# f28p65x_epwm_regs register map
Vendor: Texas Instruments
Peripheral module from a debugger description file (folder C2000).
Address unit: 16 bits
Registers are 16-bit, read-write, no defined reset value unless marked. A register's access mark holds for its fields unless they carry their own. Offsets are as the file gives them; lines under a group give offsets from that group; [hi:lo] are bit positions; {n}, {i} and the like mark numbered series; 'fields as' and 'values as' point back to an identical list; <NAME> marks a mode.

## EPWM_REGS — EPWM Registers
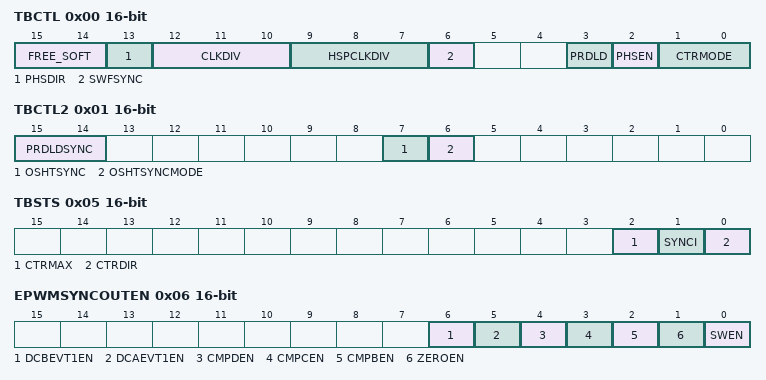
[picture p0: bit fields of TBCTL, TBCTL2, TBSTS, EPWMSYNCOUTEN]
0x00 TBCTL — Time Base Control Register
  [15:14] FREE_SOFT — Emulation Mode Bits
  [13] PHSDIR — Phase Direction Bit
  [12:10] CLKDIV — Time Base Clock Pre-scaler
  [9:7] HSPCLKDIV — High Speed TBCLK Pre-scaler
  [6] SWFSYNC — Software Force Sync Pulse
  [3] PRDLD — Active Period Load
  [2] PHSEN — Phase Load Enable
  [1:0] CTRMODE — Counter Mode
0x01 TBCTL2 — Time Base Control Register 2
  [15:14] PRDLDSYNC — PRD Shadow to Active Load on SYNC Event
  [7] OSHTSYNC — One shot sync
  [6] OSHTSYNCMODE — One shot sync mode
0x03 EPWMSYNCINSEL — EPWMxSYNCIN Source Select Register
  [6:0] SEL — EPWMxSYNCI source select
0x04 TBCTR — Time Base Counter Register
  [15:0] TBCTR — Counter Value
0x05 TBSTS access per field — Time Base Status Register
  [2] CTRMAX rw — Counter Max Latched Status
  [1] SYNCI rw — External Input Sync Status
  [0] CTRDIR ro — Counter Direction Status
0x06 EPWMSYNCOUTEN — EPWMxSYNCOUT Source Enable Register
  [6] DCBEVT1EN — EPWMxSYNCO Digital Compare B Event 1 Sync Enable
  [5] DCAEVT1EN — EPWMxSYNCO Digital Compare A Event 1 Sync Enable
  [4] CMPDEN — EPWMxSYNCO Compare D Event Enable
  [3] CMPCEN — EPWMxSYNCO Compare C Event Enable
  [2] CMPBEN — EPWMxSYNCO Compare B Event Enable
  [1] ZEROEN — EPWMxSYNCO Zero Count Event Enable
  [0] SWEN — EPWMxSYNCO Software Force Enable
0x07 TBCTL3 — Time Base Control Register 3
  [0] OSSFRCEN — One Shot Sync Force Enable
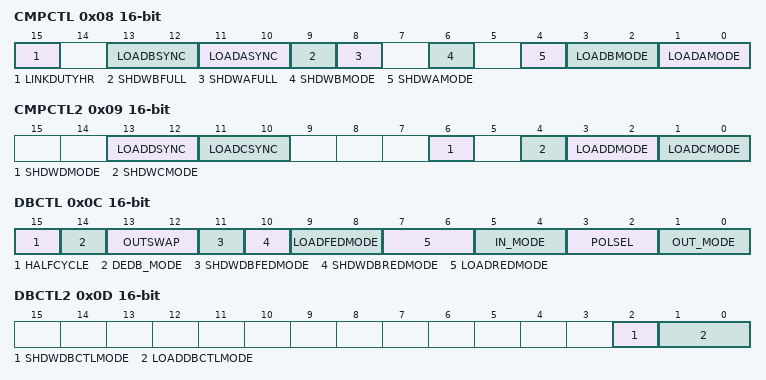
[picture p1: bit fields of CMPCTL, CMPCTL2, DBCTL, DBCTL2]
0x08 CMPCTL access per field — Counter Compare Control Register
  [15] LINKDUTYHR rw — Enable same values on CMPAHR/CMPBHR
  [13:12] LOADBSYNC rw — Active Compare B Load on SYNC
  [11:10] LOADASYNC rw — Active Compare A Load on SYNC
  [9] SHDWBFULL ro — Compare B Shadow Register Full Status
  [8] SHDWAFULL ro — Compare A Shadow Register Full Status
  [6] SHDWBMODE rw — Compare B Register Block Operating Mode
  [4] SHDWAMODE rw — Compare A Register Block Operating Mode
  [3:2] LOADBMODE rw — Active Compare B Load
  [1:0] LOADAMODE rw — Active Compare A Load
0x09 CMPCTL2 — Counter Compare Control Register 2
  [13:12] LOADDSYNC — Active Compare D Load on SYNC
  [11:10] LOADCSYNC — Active Compare C Load on SYNC
  [6] SHDWDMODE — Compare D Block Operating Mode
  [4] SHDWCMODE — Compare C Block Operating Mode
  [3:2] LOADDMODE — Active Compare D load
  [1:0] LOADCMODE — Active Compare C Load
0x0C DBCTL — Dead-Band Generator Control Register
  [15] HALFCYCLE — Half Cycle Clocking Enable
  [14] DEDB_MODE — Dead Band Dual-Edge B Mode Control
  [13:12] OUTSWAP — Dead Band Output Swap Control
  [11] SHDWDBFEDMODE — DBFED Block Operating Mode
  [10] SHDWDBREDMODE — DBRED Block Operating Mode
  [9:8] LOADFEDMODE — Active DBFED Load Mode
  [7:6] LOADREDMODE — Active DBRED Load Mode
  [5:4] IN_MODE — Dead Band Input Select Mode Control
  [3:2] POLSEL — Polarity Select Control
  [1:0] OUT_MODE — Dead Band Output Mode Control
0x0D DBCTL2 — Dead-Band Generator Control Register 2
  [2] SHDWDBCTLMODE — DBCTL Load mode Select
  [1:0] LOADDBCTLMODE — DBCTL Load from Shadow Mode Select
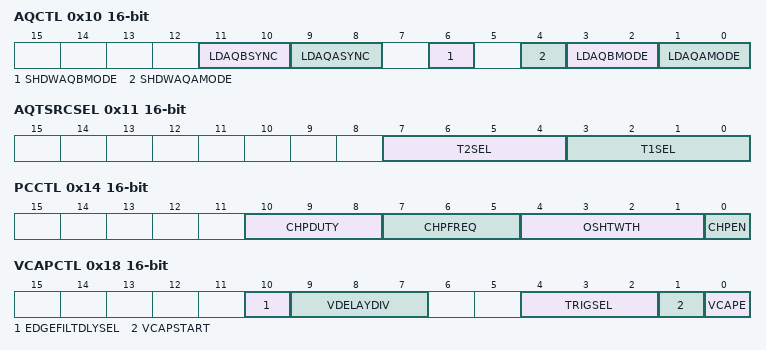
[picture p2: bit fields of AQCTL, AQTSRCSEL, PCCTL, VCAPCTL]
0x10 AQCTL — Action Qualifier Control Register
  [11:10] LDAQBSYNC — AQCTLB Register Load on SYNC
  [9:8] LDAQASYNC — AQCTLA Register Load on SYNC
  [6] SHDWAQBMODE — Action Qualifier B Operating Mode
  [4] SHDWAQAMODE — Action Qualifer A Operating Mode
  [3:2] LDAQBMODE — Action Qualifier B Load Select
  [1:0] LDAQAMODE — Action Qualifier A Load Select
0x11 AQTSRCSEL — Action Qualifier Trigger Event Source Select Register
  [7:4] T2SEL — T2 Event Source Select Bits
  [3:0] T1SEL — T1 Event Source Select Bits
0x14 PCCTL — PWM Chopper Control Register
  [10:8] CHPDUTY — Chopping clock Duty cycle
  [7:5] CHPFREQ — Chopping clock frequency
  [4:1] OSHTWTH — One-shot pulse width
  [0] CHPEN — PWM chopping enable
0x18 VCAPCTL — Valley Capture Control Register
  [10] EDGEFILTDLYSEL — Valley Switching Mode Delay Select
  [9:7] VDELAYDIV — Valley Delay Mode Divide Enable
  [4:2] TRIGSEL — Capture Trigger Select
  [1] VCAPSTART — Valley Capture Start
  [0] VCAPE — Valley Capture mode
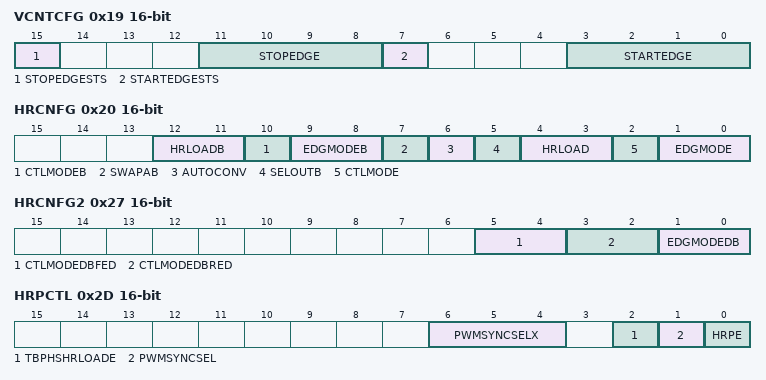
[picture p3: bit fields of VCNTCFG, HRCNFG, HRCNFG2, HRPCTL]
0x19 VCNTCFG access per field — Valley Counter Config Register
  [15] STOPEDGESTS ro — Stop Edge Status Bit
  [11:8] STOPEDGE rw — Counter Start Edge Selection
  [7] STARTEDGESTS ro — Start Edge Status Bit
  [3:0] STARTEDGE rw — Counter Start Edge Selection
0x20 HRCNFG — HRPWM Configuration Register
  [12:11] HRLOADB — ePWMxB Shadow Mode Select Bits
  [10] CTLMODEB — ePWMxB Control Mode Select Bits
  [9:8] EDGMODEB — ePWMxB Edge Mode Select Bits
  [7] SWAPAB — Swap EPWMA and EPWMB Outputs Bit
  [6] AUTOCONV — Autoconversion Bit
  [5] SELOUTB — EPWMB Output Selection Bit
  [4:3] HRLOAD — ePWMxA Shadow Mode Select Bits
  [2] CTLMODE — ePWMxA Control Mode Select Bits
  [1:0] EDGMODE — ePWMxA Edge Mode Select Bits
0x27 HRCNFG2 — HRPWM Configuration 2 Register
  [5:4] CTLMODEDBFED — DBFED Control Mode Select Bits
  [3:2] CTLMODEDBRED — DBRED Control Mode Select Bits
  [1:0] EDGMODEDB — Dead-Band Edge-Mode Select Bits
0x2D HRPCTL — High Resolution Period Control Register
  [6:4] PWMSYNCSELX — EPWMSYNCPER Extended Source Select Bit:
  [2] TBPHSHRLOADE — TBPHSHR Load Enable
  [1] PWMSYNCSEL — EPWMSYNCPER Source Select
  [0] HRPE — High Resolution Period Enable
0x2E TRREM — HRPWM High Resolution Remainder Register
  [10:0] TRREM — HRPWM Remainder Bits
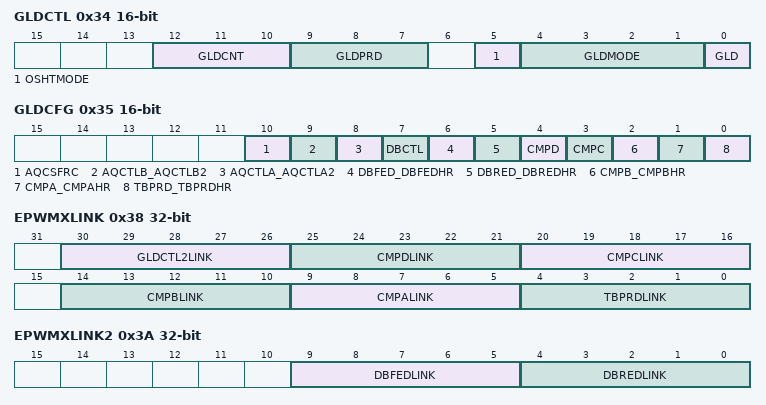
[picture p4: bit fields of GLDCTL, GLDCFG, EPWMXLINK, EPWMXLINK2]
0x34 GLDCTL access per field — Global PWM Load Control Register
  [12:10] GLDCNT ro — Global Load Strobe Counter Register
  [9:7] GLDPRD rw — Global Load Strobe Period Select Register
  [5] OSHTMODE rw — One Shot Load mode control bit
  [4:1] GLDMODE rw — Shadow to Active Global Load Pulse Selection
  [0] GLD rw — Global Shadow to Active load event control
0x35 GLDCFG — Global PWM Load Config Register
  [10] AQCSFRC — Global load event configuration for AQCSFRC
  [9] AQCTLB_AQCTLB2 — Global load event configuration for AQCTLB/B2
  [8] AQCTLA_AQCTLA2 — Global load event configuration for AQCTLA/A2
  [7] DBCTL — Global load event configuration for DBCTL
  [6] DBFED_DBFEDHR — Global load event configuration for DBFED:DBFEDHR
  [5] DBRED_DBREDHR — Global load event configuration for DBRED:DBREDHR
  [4] CMPD — Global load event configuration for CMPD
  [3] CMPC — Global load event configuration for CMPC
  [2] CMPB_CMPBHR — Global load event configuration for CMPB:CMPBHR
  [1] CMPA_CMPAHR — Global load event configuration for CMPA:CMPAHR
  [0] TBPRD_TBPRDHR — Global load event configuration for TBPRD:TBPRDHR
0x38 EPWMXLINK 32-bit
  [30:26] GLDCTL2LINK
  [25:21] CMPDLINK
  [20:16] CMPCLINK
  [14:10] CMPBLINK — CMPB:CMPBHR Link
  [9:5] CMPALINK — CMPA:CMPAHR Link
  [4:0] TBPRDLINK — TBPRD:TBPRDHR Link
0x3A EPWMXLINK2 32-bit
  [9:5] DBFEDLINK — DBFED:DBFEDHR Link
  [4:0] DBREDLINK — DBRED:DBREDHR Link
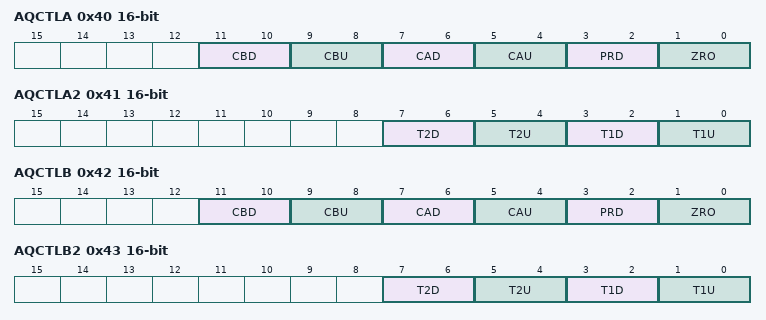
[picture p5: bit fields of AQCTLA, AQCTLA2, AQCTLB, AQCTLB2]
0x40 AQCTLA — Action Qualifier Control Register For Output A
  [11:10] CBD — Action Counter = Compare B Down
  [9:8] CBU — Action Counter = Compare B Up
  [7:6] CAD — Action Counter = Compare A Down
  [5:4] CAU — Action Counter = Compare A Up
  [3:2] PRD — Action Counter = Period
  [1:0] ZRO — Action Counter = Zero
0x41 AQCTLA2 — Additional Action Qualifier Control Register For Output A
  [7:6] T2D — Action when event occurs on T2 in DOWN-Count
  [5:4] T2U — Action when event occurs on T2 in UP-Count
  [3:2] T1D — Action when event occurs on T1 in DOWN-Count
  [1:0] T1U — Action when event occurs on T1 in UP-Count
0x42 AQCTLB — Action Qualifier Control Register For Output B
  fields as AQCTLA
0x43 AQCTLB2 — Additional Action Qualifier Control Register For Output B
  fields as AQCTLA2
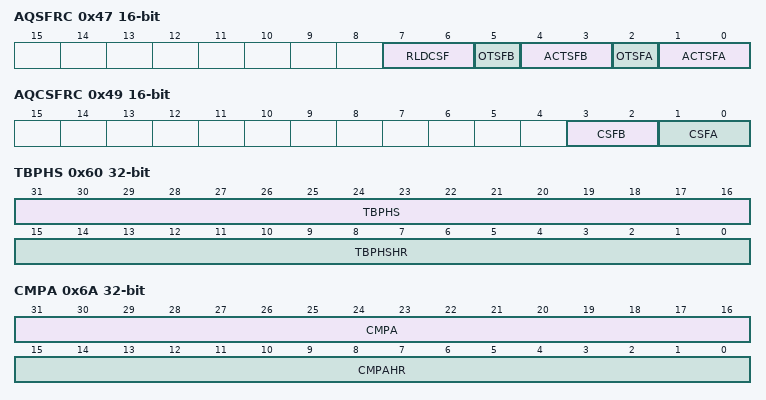
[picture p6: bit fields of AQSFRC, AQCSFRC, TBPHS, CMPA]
0x47 AQSFRC — Action Qualifier Software Force Register
  [7:6] RLDCSF — Reload from Shadow Options
  [5] OTSFB — One-time SW Force A Output
  [4:3] ACTSFB — Action when One-time SW Force B Invoked
  [2] OTSFA — One-time SW Force A Output
  [1:0] ACTSFA — Action when One-time SW Force A Invoked
0x49 AQCSFRC — Action Qualifier Continuous S/W Force Register
  [3:2] CSFB — Continuous Software Force on output B
  [1:0] CSFA — Continuous Software Force on output A
0x50 DBREDHR — Dead-Band Generator Rising Edge Delay High Resolution Mirror Register
  [15:9] DBREDHR — DBREDHR High Resolution Bits
0x51 DBRED — Dead-Band Generator Rising Edge Delay High Resolution Mirror Register
  [13:0] DBRED — Rising edge delay value
0x52 DBFEDHR — Dead-Band Generator Falling Edge Delay High Resolution Register
  [15:9] DBFEDHR — DBFEDHR High Resolution Bits
0x53 DBFED — Dead-Band Generator Falling Edge Delay Count Register
  [13:0] DBFED — Falling edge delay value
0x60 TBPHS 32-bit — Time Base Phase High
  [31:16] TBPHS — Phase Offset Register
  [15:0] TBPHSHR — Extension Register for HRPWM Phase (8-bits)
0x62 TBPRDHR — Time Base Period High Resolution Register
  [15:0] TBPRDHR — High res Time base period register
0x63 TBPRD — Time Base Period Register
  [15:0] TBPRD — Time base period register
0x6A CMPA 32-bit — Counter Compare A Register
  [31:16] CMPA — Compare A Register
  [15:0] CMPAHR — Compare A HRPWM Extension Register
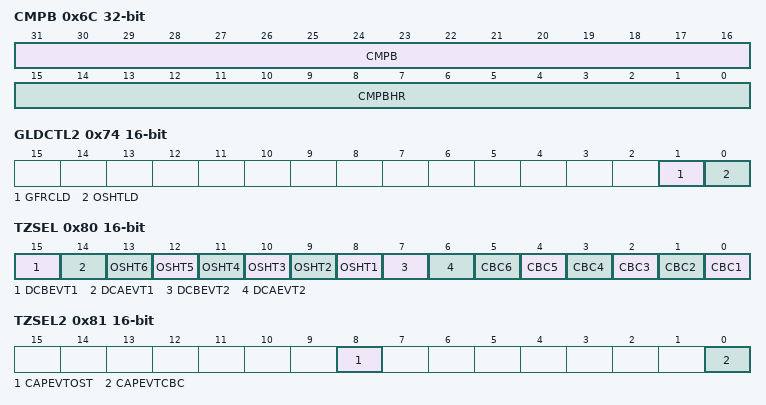
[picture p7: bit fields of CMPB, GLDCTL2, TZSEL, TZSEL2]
0x6C CMPB 32-bit — Compare B Register
  [31:16] CMPB — Compare B Register
  [15:0] CMPBHR — Compare B High Resolution Bits
0x6F CMPC — Counter Compare C Register
  [15:0] CMPC — Compare C Register
0x71 CMPD — Counter Compare D Register
  [15:0] CMPD — Compare D Register
0x74 GLDCTL2 — Global PWM Load Control Register 2
  [1] GFRCLD — Force reload event in one shot mode
  [0] OSHTLD — Enable reload event in one shot mode
0x77 SWVDELVAL — Software Valley Mode Delay Register
  [15:0] SWVDELVAL — Software programmed Valley Delay Value
0x80 TZSEL — Trip Zone Select Register
  [15] DCBEVT1 — One-shot DCBEVT1 select
  [14] DCAEVT1 — One-shot DCAEVT1 select
  [n+7] OSHT{n} (n=1..6) — One-shot TZ{n} select
  [7] DCBEVT2 — DCBEVT2 CBC select
  [6] DCAEVT2 — DCAEVT2 CBC select
  [n-1] CBC{n} (n=1..6) — TZ{n} CBC select
0x81 TZSEL2 — Trip Zone Select Register 2
  [8] CAPEVTOST — CAPEVT One-shot select
  [0] CAPEVTCBC — CAPEVT CBC select
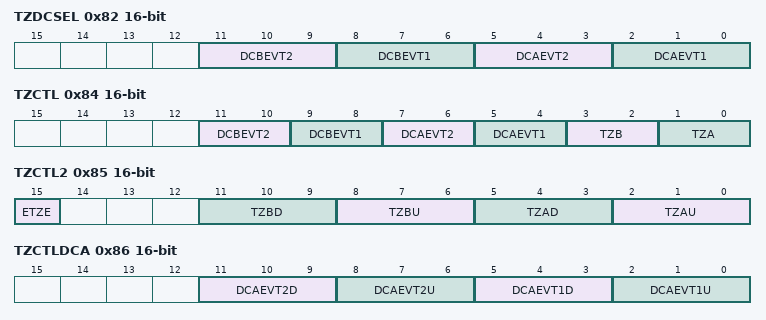
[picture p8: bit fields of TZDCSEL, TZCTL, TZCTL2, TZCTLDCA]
0x82 TZDCSEL — Trip Zone Digital Comparator Select Register
  [11:9] DCBEVT2 — Digital Compare Output B Event 2
  [8:6] DCBEVT1 — Digital Compare Output B Event 1
  [5:3] DCAEVT2 — Digital Compare Output A Event 2
  [2:0] DCAEVT1 — Digital Compare Output A Event 1
0x84 TZCTL — Trip Zone Control Register
  [11:10] DCBEVT2 — EPWMxB action on DCBEVT2
  [9:8] DCBEVT1 — EPWMxB action on DCBEVT1
  [7:6] DCAEVT2 — EPWMxA action on DCAEVT2
  [5:4] DCAEVT1 — EPWMxA action on DCAEVT1
  [3:2] TZB — TZ1 to TZ6 Trip Action On EPWMxB
  [1:0] TZA — TZ1 to TZ6 Trip Action On EPWMxA
0x85 TZCTL2 — Additional Trip Zone Control Register
  [15] ETZE — TZCTL2 Enable
  [11:9] TZBD — Trip Action On EPWMxB while Count direction is DOWN
  [8:6] TZBU — Trip Action On EPWMxB while Count direction is UP
  [5:3] TZAD — Trip Action On EPWMxA while Count direction is DOWN
  [2:0] TZAU — Trip Action On EPWMxA while Count direction is UP
0x86 TZCTLDCA — Trip Zone Control Register Digital Compare A
  [11:9] DCAEVT2D — DCAEVT2 Action On EPWMxA while Count direction is DOWN
  [8:6] DCAEVT2U — DCAEVT2 Action On EPWMxA while Count direction is UP
  [5:3] DCAEVT1D — DCAEVT1 Action On EPWMxA while Count direction is DOWN
  [2:0] DCAEVT1U — DCAEVT1 Action On EPWMxA while Count direction is UP
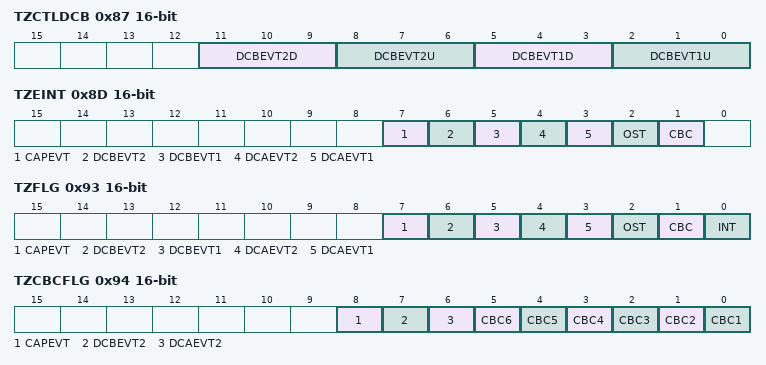
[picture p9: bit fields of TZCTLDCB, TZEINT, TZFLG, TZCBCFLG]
0x87 TZCTLDCB — Trip Zone Control Register Digital Compare B
  [11:9] DCBEVT2D — DCBEVT2 Action On EPWMxA while Count direction is DOWN
  [8:6] DCBEVT2U — DCBEVT2 Action On EPWMxA while Count direction is UP
  [5:3] DCBEVT1D — DCBEVT1 Action On EPWMxA while Count direction is DOWN
  [2:0] DCBEVT1U — DCBEVT1 Action On EPWMxA while Count direction is UP
0x8D TZEINT — Trip Zone Enable Interrupt Register
  [7] CAPEVT — Capture Eveent Interrupt Enable
  [6] DCBEVT2 — Digital Compare B Event 2 Int Enable
  [5] DCBEVT1 — Digital Compare B Event 1 Int Enable
  [4] DCAEVT2 — Digital Compare A Event 2 Int Enable
  [3] DCAEVT1 — Digital Compare A Event 1 Int Enable
  [2] OST — Trip Zones One Shot Int Enable
  [1] CBC — Trip Zones Cycle By Cycle Int Enable
0x93 TZFLG ro — Trip Zone Flag Register
  [7] CAPEVT — Capture Event Flag
  [6] DCBEVT2 — Digital Compare B Event 2 Flag
  [5] DCBEVT1 — Digital Compare B Event 1 Flag
  [4] DCAEVT2 — Digital Compare A Event 2 Flag
  [3] DCAEVT1 — Digital Compare A Event 1 Flag
  [2] OST — Trip Zones One Shot Flag
  [1] CBC — Trip Zones Cycle By Cycle Flag
  [0] INT — Global Int Status Flag
0x94 TZCBCFLG ro — Trip Zone CBC Flag Register
  [8] CAPEVT — Capture Event Flag
  [7] DCBEVT2 — Latched Status Flag for Digital Compare Output B Event 2
  [6] DCAEVT2 — Latched Status Flag for Digital Compare Output A Event 2
  [n-1] CBC{n} (n=1..6) — Latched Status Flag for CBC{n} Trip Latch
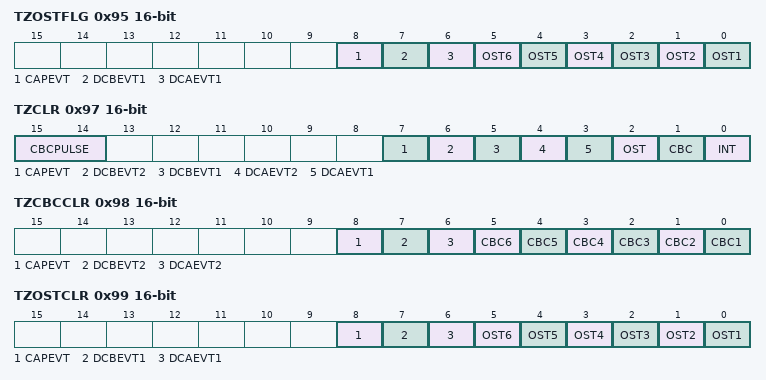
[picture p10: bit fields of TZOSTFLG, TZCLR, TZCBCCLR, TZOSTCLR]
0x95 TZOSTFLG ro — Trip Zone OST Flag Register
  [8] CAPEVT — Capture Event Flag
  [7] DCBEVT1 — Latched Status Flag for Digital Compare Output B Event 1
  [6] DCAEVT1 — Latched Status Flag for Digital Compare Output A Event 1
  [n-1] OST{n} (n=1..6) — Latched Status Flag for OST{n} Trip Latch
0x97 TZCLR — Trip Zone Clear Register
  [15:14] CBCPULSE — Clear Pulse for CBC Trip Latch
  [7] CAPEVT — Capture Event Clear
  [6] DCBEVT2 — DCBEVT2 Flag Clear
  [5] DCBEVT1 — DCBEVT1 Flag Clear
  [4] DCAEVT2 — DCAEVT2 Flag Clear
  [3] DCAEVT1 — DCAVET1 Flag Clear
  [2] OST — One-Shot Flag Clear
  [1] CBC — Cycle-By-Cycle Flag Clear
  [0] INT — Global Interrupt Clear Flag
0x98 TZCBCCLR — Trip Zone CBC Clear Register
  [8] CAPEVT — Clear Flag for CAPEVT selected for CBC
  [7] DCBEVT2 — Clear Flag for DCBEVT2 selected for CBC
  [6] DCAEVT2 — Clear Flag forDCAEVT2 selected for CBC
  [n-1] CBC{n} (n=1..6) — Clear Flag for Cycle-By-Cycle (CBC{n}) Trip Latch
0x99 TZOSTCLR — Trip Zone OST Clear Register
  [8] CAPEVT — Clear Flag for CAPEVT selected for OST
  [7] DCBEVT1 — Clear Flag for DCBEVT1 selected for OST
  [6] DCAEVT1 — Clear Flag for DCAEVT1 selected for OST
  [n-1] OST{n} (n=1..6) — Clear Flag for Oneshot (OST{n}) Trip Latch
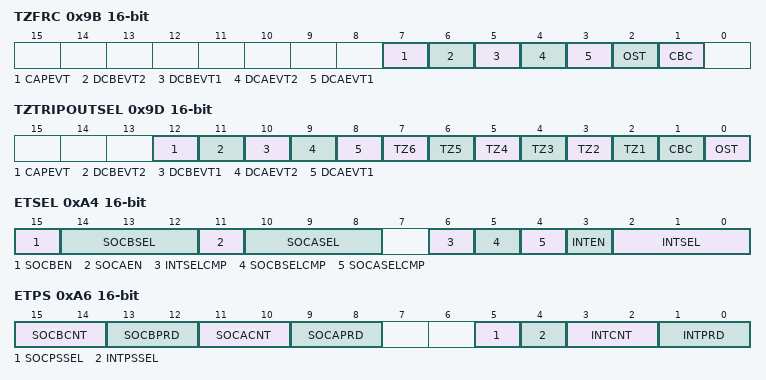
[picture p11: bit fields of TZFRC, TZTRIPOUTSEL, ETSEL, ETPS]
0x9B TZFRC — Trip Zone Force Register
  [7] CAPEVT — Force Capture Event
  [6] DCBEVT2 — Force Digital Compare B Event 2
  [5] DCBEVT1 — Force Digital Compare B Event 1
  [4] DCAEVT2 — Force Digital Compare A Event 2
  [3] DCAEVT1 — Force Digital Compare A Event 1
  [2] OST — Force Trip Zones One Shot Event
  [1] CBC — Force Trip Zones Cycle By Cycle Event
0x9D TZTRIPOUTSEL — Trip Out Select Register
  [12] CAPEVT — CAPEVT TRIPOUT select
  [11] DCBEVT2 — DCBEVT2.force TRIPOUT select
  [10] DCBEVT1 — DCBEVT1.force TRIPOUT select
  [9] DCAEVT2 — DCAEVT2.force TRIPOUT select
  [8] DCAEVT1 — DCAEVT1.force TRIPOUT select
  [n+1] TZ{n} (n=1..6) — TZ{n} TRIPOUT select
  [1] CBC — CBC TRIPOUT select
  [0] OST — OST TRIPOUT select
0xA4 ETSEL — Event Trigger Selection Register
  [15] SOCBEN — Start of Conversion B Enable
  [14:12] SOCBSEL — Start of Conversion B Select
  [11] SOCAEN — Start of Conversion A Enable
  [10:8] SOCASEL — Start of Conversion A Select
  [6] INTSELCMP — EPWMxINT Compare Select
  [5] SOCBSELCMP — EPWMxSOCB Compare Select
  [4] SOCASELCMP — EPWMxSOCA Compare Select
  [3] INTEN — EPWMxINTn Enable
  [2:0] INTSEL — EPWMxINTn Select
0xA6 ETPS access per field — Event Trigger Pre-Scale Register
  [15:14] SOCBCNT ro — EPWMxSOCB Counter
  [13:12] SOCBPRD rw — EPWMxSOCB Period Select
  [11:10] SOCACNT ro — EPWMxSOCA Counter Register
  [9:8] SOCAPRD rw — EPWMxSOCA Period Select
  [5] SOCPSSEL rw — EPWMxSOC A/B Pre-Scale Selection Bits
  [4] INTPSSEL rw — EPWMxINTn Pre-Scale Selection Bits
  [3:2] INTCNT ro — EPWMxINTn Counter Register
  [1:0] INTPRD rw — EPWMxINTn Period Select
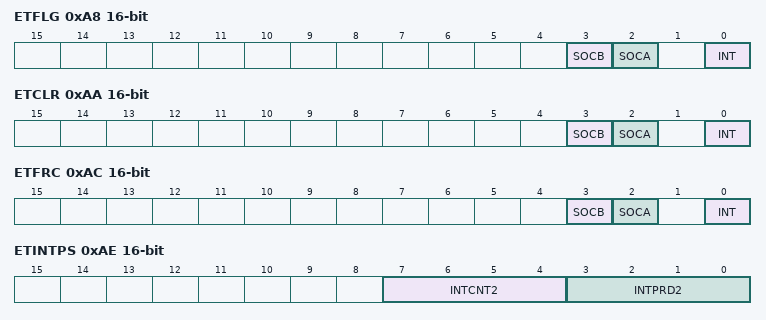
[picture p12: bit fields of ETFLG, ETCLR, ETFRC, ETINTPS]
0xA8 ETFLG ro — Event Trigger Flag Register
  [3] SOCB — EPWMxSOCB Flag
  [2] SOCA — EPWMxSOCA Flag
  [0] INT — EPWMxINTn Flag
0xAA ETCLR — Event Trigger Clear Register
  [3] SOCB — EPWMxSOCB Clear
  [2] SOCA — EPWMxSOCA Clear
  [0] INT — EPWMxINTn Clear
0xAC ETFRC — Event Trigger Force Register
  [3] SOCB — EPWMxSOCB Force
  [2] SOCA — EPWMxSOCA Force
  [0] INT — EPWMxINTn Force
0xAE ETINTPS access per field — Event-Trigger Interrupt Pre-Scale Register
  [7:4] INTCNT2 ro — EPWMxINTn Counter Register
  [3:0] INTPRD2 rw — EPWMxINTn Period Select
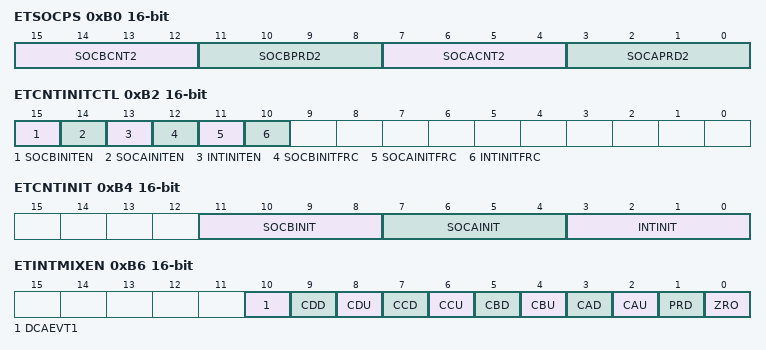
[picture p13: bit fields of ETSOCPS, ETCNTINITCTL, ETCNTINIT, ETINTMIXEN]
0xB0 ETSOCPS access per field — Event-Trigger SOC Pre-Scale Register
  [15:12] SOCBCNT2 ro — EPWMxSOCB Counter Register
  [11:8] SOCBPRD2 rw — EPWMxSOCB Period Select
  [7:4] SOCACNT2 ro — EPWMxSOCA Counter Register
  [3:0] SOCAPRD2 rw — EPWMxSOCA Period Select
0xB2 ETCNTINITCTL — Event-Trigger Counter Initialization Control Register
  [15] SOCBINITEN — EPWMxSOCB Counter Initialization Enable
  [14] SOCAINITEN — EPWMxSOCA Counter Initialization Enable
  [13] INTINITEN — EPWMxINT Counter Initialization Enable
  [12] SOCBINITFRC — EPWMxSOCB Counter Initialization Force
  [11] SOCAINITFRC — EPWMxSOCA Counter Initialization Force
  [10] INTINITFRC — EPWMxINT Counter Initialization Force
0xB4 ETCNTINIT — Event-Trigger Counter Initialization Register
  [11:8] SOCBINIT — EPWMxSOCB Counter Initialization Bits
  [7:4] SOCAINIT — EPWMxSOCA Counter Initialization Bits
  [3:0] INTINIT — EPWMxINT Counter Initialization Bits
0xB6 ETINTMIXEN — Event-Trigger Mixed INT Selection
  [10] DCAEVT1 — DCAEVT1.inter enable to ETINTMIX
  [9] CDD — CMPD down-count match enable to ETINTMIX
  [8] CDU — CMPD up-count match enable to ETINTMIX
  [7] CCD — CMPC down-count match enable to ETINTMIX
  [6] CCU — CMPC up-count match enable to ETINTMIX
  [5] CBD — CMPB down-count match enable to ETINTMIX
  [4] CBU — CMPB up-count match enable to ETINTMIX
  [3] CAD — CMPA down-count match enable to ETINTMIX
  [2] CAU — CMPA up-count match enable to ETINTMIX
  [1] PRD — Period match enable to ETINTMIX
  [0] ZRO — Zero match enable to ETINTMIX
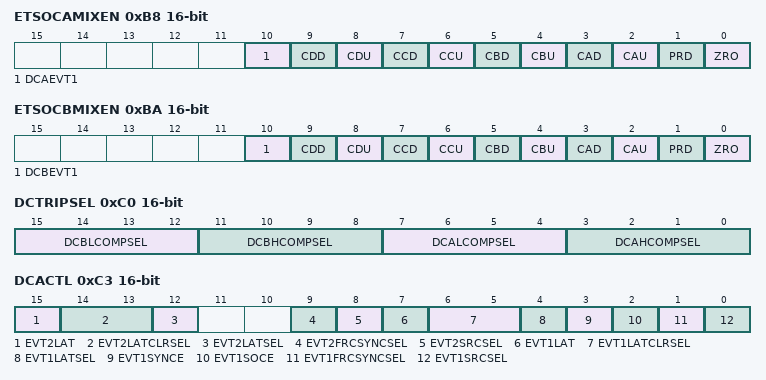
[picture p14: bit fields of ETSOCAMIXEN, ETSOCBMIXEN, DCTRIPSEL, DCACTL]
0xB8 ETSOCAMIXEN — Event-Trigger Mixed SOCA Selection
  [10] DCAEVT1 — DCAEVT1.inter enable to ETSOCAMIX
  [9] CDD — CMPD down-count match enable to ETSOCAMIX
  [8] CDU — CMPD up-count match enable to ETSOCAMIX
  [7] CCD — CMPC down-count match enable to ETSOCAMIX
  [6] CCU — CMPC up-count match enable to ETSOCAMIX
  [5] CBD — CMPB down-count match enable to ETSOCAMIX
  [4] CBU — CMPB up-count match enable to ETSOCAMIX
  [3] CAD — CMPA down-count match enable to ETSOCAMIX
  [2] CAU — CMPA up-count match enable to ETSOCAMIX
  [1] PRD — Period match enable to ETSOCAMIX
  [0] ZRO — Zero match enable to ETSOCAMIX
0xBA ETSOCBMIXEN — Event-Trigger Mixed SOCB Selection
  [10] DCBEVT1 — DCBEVT1.inter enable to ETSOCBMIX
  [9] CDD — CMPD down-count match enable to ETSOCBMIX
  [8] CDU — CMPD up-count match enable to ETSOCBMIX
  [7] CCD — CMPC down-count match enable to ETSOCBMIX
  [6] CCU — CMPC up-count match enable to ETSOCBMIX
  [5] CBD — CMPB down-count match enable to ETSOCBMIX
  [4] CBU — CMPB up-count match enable to ETSOCBMIX
  [3] CAD — CMPA down-count match enable to ETSOCBMIX
  [2] CAU — CMPA up-count match enable to ETSOCBMIX
  [1] PRD — Period match enable to ETSOCBMIX
  [0] ZRO — Zero match enable to ETSOCBMIX
0xC0 DCTRIPSEL — Digital Compare Trip Select Register
  [15:12] DCBLCOMPSEL — Digital Compare B Low COMP Input Select
  [11:8] DCBHCOMPSEL — Digital Compare B High COMP Input Select
  [7:4] DCALCOMPSEL — Digital Compare A Low COMP Input Select
  [3:0] DCAHCOMPSEL — Digital Compare A High COMP Input Select
0xC3 DCACTL access per field — Digital Compare A Control Register
  [15] EVT2LAT ro — Indicates the status of DCAEVT2LAT signal.
  [14:13] EVT2LATCLRSEL rw — DCAEVT2 Latched clear source select
  [12] EVT2LATSEL rw — DCAEVT2 Latched signal select
  [9] EVT2FRCSYNCSEL rw — DCAEVT2 Force Sync Signal
  [8] EVT2SRCSEL rw — DCAEVT2 Source Signal
  [7] EVT1LAT ro — Indicates the status of DCAEVT1LAT signal.
  [6:5] EVT1LATCLRSEL rw — DCAEVT1 Latched clear source select
  [4] EVT1LATSEL rw — DCAEVT1 Latched signal select
  [3] EVT1SYNCE rw — DCAEVT1 SYNC Enable
  [2] EVT1SOCE rw — DCAEVT1 SOC Enable
  [1] EVT1FRCSYNCSEL rw — DCAEVT1 Force Sync Signal
  [0] EVT1SRCSEL rw — DCAEVT1 Source Signal
0xC4 DCBCTL access per field — Digital Compare B Control Register
  [15] EVT2LAT ro — Indicates the status of DCBEVT2LAT signal.
  [14:13] EVT2LATCLRSEL rw — DCBEVT2 Latched clear source select
  [12] EVT2LATSEL rw — DCBEVT2 Latched signal select
  [9] EVT2FRCSYNCSEL rw — DCBEVT2 Force Sync Signal
  [8] EVT2SRCSEL rw — DCBEVT2 Source Signal
  [7] EVT1LAT ro — Indicates the status of DCBEVT1LAT signal.
  [6:5] EVT1LATCLRSEL rw — DCBEVT1 Latched clear source select
  [4] EVT1LATSEL rw — DCBEVT1 Latched signal select
  [3] EVT1SYNCE rw — DCBEVT1 SYNC Enable
  [2] EVT1SOCE rw — DCBEVT1 SOC Enable
  [1] EVT1FRCSYNCSEL rw — DCBEVT1 Force Sync Signal
  [0] EVT1SRCSEL rw — DCBEVT1 Source Signal
0xC7 DCFCTL access per field — Digital Compare Filter Control Register
  [15:13] EDGESTATUS ro
  [12:10] EDGECOUNT rw
  [9:8] EDGEMODE rw
  [6] EDGEFILTSEL rw — Edge Filter Select
  [5:4] PULSESEL rw — Pulse Select for Blanking and Capture Alignment
  [3] BLANKINV rw — Blanking Window Inversion
  [2] BLANKE rw — Blanking Enable/Disable
  [1:0] SRCSEL rw — Filter Block Signal Source Select
0xC8 DCCAPCTL access per field — Digital Compare Capture Control Register
  [15] CAPMODE rw — Counter Capture Mode
  [14] CAPCLR rw — DC Capture Latched Status Clear Flag
  [13] CAPSTS ro — Latched Status Flag for Capture Event
  [1] SHDWMODE rw — Counter Capture Mode
  [0] CAPE rw — Counter Capture Enable
0xC9 DCFOFFSET — Digital Compare Filter Offset Register
  [15:0] DCFOFFSET — Blanking Offset
0xCA DCFOFFSETCNT ro — Digital Compare Filter Offset Counter Register
  [15:0] DCFOFFSETCNT — Blanking Offset Counter
0xCB DCFWINDOW — Digital Compare Filter Window Register
0xCC DCFWINDOWCNT ro — Digital Compare Filter Window Counter Register
0xCD BLANKPULSEMIXSEL — Blanking window trigger pulse select register
  [9] CDD — CMPD down-count match enable to BLANKPULSEMIX
  [8] CDU — CMPD up-count match enable to BLANKPULSEMIX
  [7] CCD — CMPC down-count match enable to BLANKPULSEMIX
  [6] CCU — CMPC up-count match enable to BLANKPULSEMIX
  [5] CBD — CMPB down-count match enable to BLANKPULSEMIX
  [4] CBU — CMPB up-count match enable to BLANKPULSEMIX
  [3] CAD — CMPA down-count match enable to BLANKPULSEMIX
  [2] CAU — CMPA up-count match enable to BLANKPULSEMIX
  [1] PRD — Period match enable to BLANKPULSEMIX
  [0] ZRO — Zero match enable to BLANKPULSEMIX
0xCE DCCAPMIXSEL — Capture Event pulse select register
  [9] CDD — CMPD down-count match enable to DCCAPMIX
  [8] CDU — CMPD up-count match enable to DCCAPMIX
  [7] CCD — CMPC down-count match enable to DCCAPMIX
  [6] CCU — CMPC up-count match enable to DCCAPMIX
  [5] CBD — CMPB down-count match enable to DCCAPMIX
  [4] CBU — CMPB up-count match enable to DCCAPMIX
  [3] CAD — CMPA down-count match enable to DCCAPMIX
  [2] CAU — CMPA up-count match enable to DCCAPMIX
  [1] PRD — Period match enable to DCCAPMIX
  [0] ZRO — Zero match enable to DCCAPMIX
0xCF DCCAP ro — Digital Compare Counter Capture Register
  [15:0] DCCAP — Time Base Counter Capture Register
0xD2 DCAHTRIPSEL — Digital Compare AH Trip Select
  [14] TRIPINPUT15 — Trip Input 15 Select to DCAH Mux
  [13] TRIPINPUT14 — Trip Input 14 Select to DCAH Mux
  [n-1] TRIPINPUT{n} (n=1..12) — Trip Input {n} Select to DCAH Mux
0xD3 DCALTRIPSEL — Digital Compare AL Trip Select
  [14] TRIPINPUT15 — Trip Input 15 Select to DCAL Mux
  [13] TRIPINPUT14 — Trip Input 14 Select to DCAL Mux
  [n-1] TRIPINPUT{n} (n=1..12) — Trip Input {n} Select to DCAL Mux
0xD4 DCBHTRIPSEL — Digital Compare BH Trip Select
  [14] TRIPINPUT15 — Trip Input 15 Select to DCBH Mux
  [13] TRIPINPUT14 — Trip Input 14 Select to DCBH Mux
  [n-1] TRIPINPUT{n} (n=1..12) — Trip Input {n} Select to DCBH Mux
0xD5 DCBLTRIPSEL — Digital Compare BL Trip Select
  [14] TRIPINPUT15 — Trip Input 15 Select to DCBL Mux
  [13] TRIPINPUT14 — Trip Input 14 Select to DCBL Mux
  [n-1] TRIPINPUT{n} (n=1..12) — Trip Input {n} Select to DCBL Mux
0xD6 CAPCTL — Event Capture Control Register
  [8] FRCLOAD — Capture event force load
  [4] PULSECTL — Polarity selection for Capture input
  [3] CAPINPOL — Polarity selection for Capture input
  [2:1] CAPGATEPOL — Polarity selection for Capture Gate input
  [0] SRCSEL — Capture Logic Input Selection
0xD7 CAPGATETRIPSEL — Event Capture Gate Trip input select
  [14] TRIPINPUT15 — Trip Input 15 Select to CAPGATE Mux
  [13] TRIPINPUT14 — Trip Input 14 Select to CAPGATE Mux
  [n-1] TRIPINPUT{n} (n=1..12) — Trip Input {n} Select to CAPGATE Mux
0xD8 CAPINTRIPSEL — Event Capture Trip input select
  [14] TRIPINPUT15 — Trip Input 15 Select to CAPIN Mux
  [13] TRIPINPUT14 — Trip Input 14 Select to CAPIN Mux
  [n-1] TRIPINPUT{n} (n=1..12) — Trip Input {n} Select to CAPIN Mux
0xD9 CAPTRIPSEL — Event Capture Signal Select
  [7:4] CAPGATECOMPSEL — CAPGATE Comparator COMP Input Select
  [3:0] CAPINCOMPSEL — CAPIN Comparator Input Select
0xFA EPWMLOCK 32-bit
  [31:16] KEY — Key to write to this register
  [4] DCLOCK — Digital Compare Register Set Lock
  [3] TZCLRLOCK — TripZone Clear Register Set Lock
  [2] TZCFGLOCK — TripZone Register Set Lock
  [1] GLLOCK — Global Load Register Set Lock
  [0] HRLOCK — HRPWM Register Set Lock
0xFD HWVDELVAL ro — Hardware Valley Mode Delay Register
  [15:0] HWVDELVAL — Hardware programmed Valley Delay Value
0xFE VCNTVAL ro — Hardware Valley Counter Register
  [15:0] VCNTVAL — Valley Counter Value
